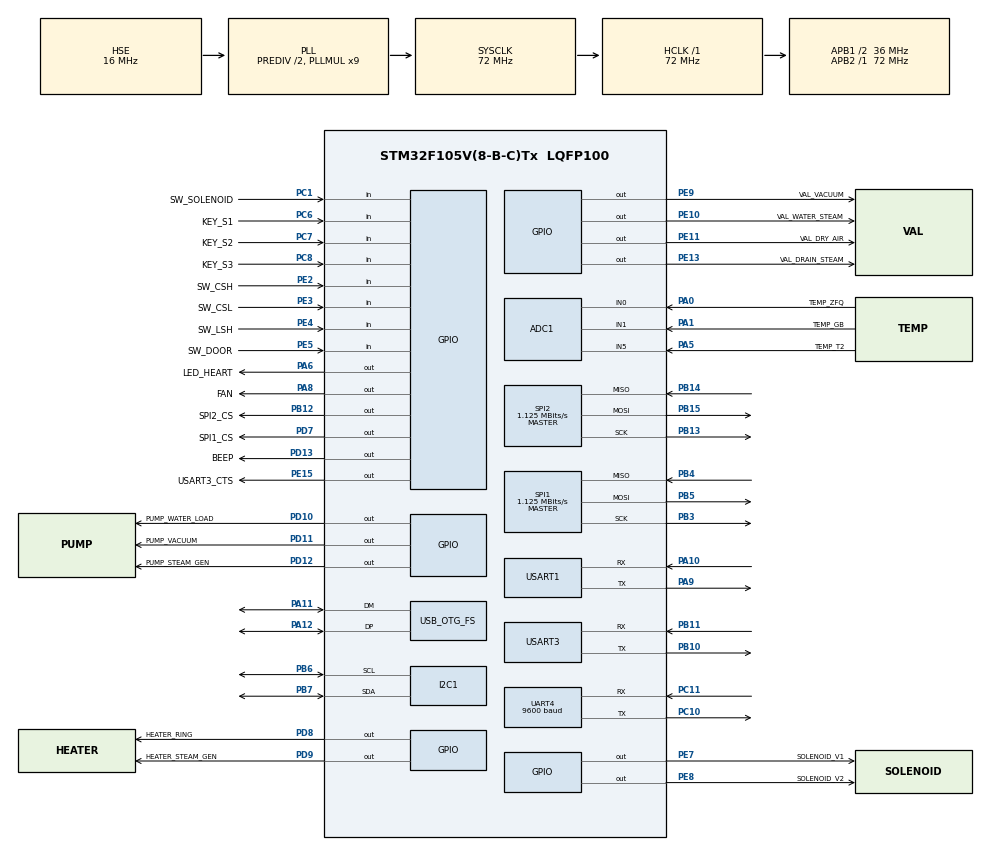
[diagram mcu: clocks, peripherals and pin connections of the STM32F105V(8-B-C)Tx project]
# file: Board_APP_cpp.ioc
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ADC1.Channel-0\#ChannelRegularConversion=ADC_CHANNEL_0
ADC1.ContinuousConvMode=DISABLE
ADC1.DiscontinuousConvMode=DISABLE
ADC1.NbrOfConversion=1
ADC1.NbrOfConversionFlag=1
ADC1.Rank-0\#ChannelRegularConversion=1
ADC1.SamplingTime-0\#ChannelRegularConversion=ADC_SAMPLETIME_28CYCLES_5
ADC1.master=1
Dma.I2C1_RX.1.Direction=DMA_PERIPH_TO_MEMORY
Dma.I2C1_RX.1.Instance=DMA1_Channel7
Dma.I2C1_RX.1.MemDataAlignment=DMA_MDATAALIGN_BYTE
Dma.I2C1_RX.1.MemInc=DMA_MINC_ENABLE
Dma.I2C1_RX.1.Mode=DMA_NORMAL
Dma.I2C1_RX.1.PeriphDataAlignment=DMA_PDATAALIGN_BYTE
Dma.I2C1_RX.1.PeriphInc=DMA_PINC_DISABLE
Dma.I2C1_RX.1.Priority=DMA_PRIORITY_LOW
Dma.I2C1_TX.2.Direction=DMA_MEMORY_TO_PERIPH
Dma.I2C1_TX.2.Instance=DMA1_Channel6
Dma.I2C1_TX.2.MemDataAlignment=DMA_MDATAALIGN_BYTE
Dma.I2C1_TX.2.MemInc=DMA_MINC_ENABLE
Dma.I2C1_TX.2.Mode=DMA_NORMAL
Dma.I2C1_TX.2.PeriphDataAlignment=DMA_PDATAALIGN_BYTE
Dma.I2C1_TX.2.PeriphInc=DMA_PINC_DISABLE
Dma.I2C1_TX.2.Priority=DMA_PRIORITY_LOW
Dma.Request0=USART3_RX
Dma.Request1=I2C1_RX
Dma.Request2=I2C1_TX
Dma.USART3_RX.0.Direction=DMA_PERIPH_TO_MEMORY
Dma.USART3_RX.0.Instance=DMA1_Channel3
Dma.USART3_RX.0.MemDataAlignment=DMA_MDATAALIGN_BYTE
Dma.USART3_RX.0.MemInc=DMA_MINC_ENABLE
Dma.USART3_RX.0.Mode=DMA_NORMAL
Dma.USART3_RX.0.PeriphDataAlignment=DMA_PDATAALIGN_BYTE
Dma.USART3_RX.0.PeriphInc=DMA_PINC_DISABLE
Dma.USART3_RX.0.Priority=DMA_PRIORITY_LOW
FREERTOS.Tasks01=taskAlive,-2,1024,StartTaskAlive,Default,NULL,Dynamic,NULL,NULL
FREERTOS.configTOTAL_HEAP_SIZE=8192
FREERTOS.configUSE_NEWLIB_REENTRANT=1
Mcu.Family=STM32F1
Mcu.Name=STM32F105V(8-B-C)Tx
Mcu.Package=LQFP100
NVIC.DMA1_Channel3_IRQn=true\:5\:0\:false\:false\:true\:true\:false\:true\:true
NVIC.DMA1_Channel6_IRQn=true\:5\:0\:false\:false\:true\:true\:false\:true\:true
NVIC.DMA1_Channel7_IRQn=true\:5\:0\:false\:false\:true\:true\:false\:true\:true
NVIC.PriorityGroup=NVIC_PRIORITYGROUP_4
NVIC.TIM6_IRQn=true\:0\:0\:true\:false\:true\:false\:false\:true\:true
NVIC.TimeBase=TIM6_IRQn
NVIC.TimeBaseIP=TIM6
NVIC.USART3_IRQn=true\:5\:0\:false\:false\:true\:true\:true\:true\:true
OSC_IN.Mode=HSE-External-Oscillator
OSC_IN.Signal=RCC_OSC_IN
OSC_OUT.Mode=HSE-External-Oscillator
OSC_OUT.Signal=RCC_OSC_OUT
PA0-WKUP.GPIO_Label=TEMP_ZFQ
PA0-WKUP.Signal=ADCx_IN0
PA1.GPIO_Label=TEMP_GB
PA1.Signal=ADCx_IN1
PA10.Mode=Asynchronous
PA10.Signal=USART1_RX
PA11.Mode=Host_Only
PA11.Signal=USB_OTG_FS_DM
PA12.Mode=Host_Only
PA12.Signal=USB_OTG_FS_DP
PA13.Mode=Serial_Wire
PA13.Signal=SYS_JTMS-SWDIO
PA14.Mode=Serial_Wire
PA14.Signal=SYS_JTCK-SWCLK
PA5.GPIO_Label=TEMP_T2
PA5.Signal=ADCx_IN5
PA6.GPIO_Label=LED_HEART
PA6.Signal=GPIO_Output
PA8.GPIO_Label=FAN
PA8.Signal=GPIO_Output
PA9.Mode=Asynchronous
PA9.Signal=USART1_TX
PB10.Mode=Asynchronous
PB10.Signal=USART3_TX
PB11.Mode=Asynchronous
PB11.Signal=USART3_RX
PB12.GPIO_Label=SPI2_CS
PB12.Signal=GPIO_Output
PB13.Mode=Full_Duplex_Master
PB13.Signal=SPI2_SCK
PB14.Mode=Full_Duplex_Master
PB14.Signal=SPI2_MISO
PB15.Mode=Full_Duplex_Master
PB15.Signal=SPI2_MOSI
PB3.Mode=Full_Duplex_Master
PB3.Signal=SPI1_SCK
PB4.Mode=Full_Duplex_Master
PB4.Signal=SPI1_MISO
PB5.Mode=Full_Duplex_Master
PB5.Signal=SPI1_MOSI
PB6.Mode=I2C
PB6.Signal=I2C1_SCL
PB7.Mode=I2C
PB7.Signal=I2C1_SDA
PC1.GPIO_Label=SW_SOLENOID
PC1.Signal=GPIO_Input
PC10.Mode=Asynchronous
PC10.Signal=UART4_TX
PC11.Mode=Asynchronous
PC11.Signal=UART4_RX
PC6.GPIO_Label=KEY_S1
PC6.Signal=GPIO_Input
PC7.GPIO_Label=KEY_S2
PC7.Signal=GPIO_Input
PC8.GPIO_Label=KEY_S3
PC8.Signal=GPIO_Input
PD10.GPIO_Label=PUMP_WATER_LOAD
PD10.Signal=GPIO_Output
PD11.GPIO_Label=PUMP_VACUUM
PD11.Signal=GPIO_Output
PD12.GPIO_Label=PUMP_STEAM_GEN
PD12.Signal=GPIO_Output
PD13.GPIO_Label=BEEP
PD13.Signal=GPIO_Output
PD7.GPIO_Label=SPI1_CS
PD7.Signal=GPIO_Output
PD8.GPIO_Label=HEATER_RING
PD8.Signal=GPIO_Output
PD9.GPIO_Label=HEATER_STEAM_GEN
PD9.Signal=GPIO_Output
PE10.GPIO_Label=VAL_WATER_STEAM
PE10.Signal=GPIO_Output
PE11.GPIO_Label=VAL_DRY_AIR
PE11.Signal=GPIO_Output
PE13.GPIO_Label=VAL_DRAIN_STEAM
PE13.Signal=GPIO_Output
PE15.GPIO_Label=USART3_CTS
PE15.Signal=GPIO_Output
PE2.GPIO_Label=SW_CSH
PE2.Signal=GPIO_Input
PE3.GPIO_Label=SW_CSL
PE3.Signal=GPIO_Input
PE4.GPIO_Label=SW_LSH
PE4.Signal=GPIO_Input
PE5.GPIO_Label=SW_DOOR
PE5.Signal=GPIO_Input
PE7.GPIO_Label=SOLENOID_V1
PE7.Signal=GPIO_Output
PE8.GPIO_Label=SOLENOID_V2
PE8.Signal=GPIO_Output
PE9.GPIO_Label=VAL_VACUUM
PE9.Signal=GPIO_Output
ProjectManager.HeapSize=0x200
ProjectManager.StackSize=0x400
ProjectManager.TargetToolchain=STM32CubeIDE
RCC.ADCPresc=RCC_ADCPCLK2_DIV6
RCC.AHBFreq_Value=72000000
RCC.APB1CLKDivider=RCC_HCLK_DIV2
RCC.APB1Freq_Value=36000000
RCC.APB1TimFreq_Value=72000000
RCC.APB2Freq_Value=72000000
RCC.APB2TimFreq_Value=72000000
RCC.HCLKFreq_Value=72000000
RCC.HSEDivPLL=RCC_HSE_PREDIV_DIV2
RCC.HSE_VALUE=16000000
RCC.PLLMUL=RCC_PLL_MUL9
RCC.PLLSourceVirtual=RCC_PLLSOURCE_HSE
RCC.SYSCLKFreq_VALUE=72000000
RCC.SYSCLKSource=RCC_SYSCLKSOURCE_PLLCLK
RCC.USBFreq_Value=48000000
SH.ADCx_IN0.0=ADC1_IN0,IN0
SH.ADCx_IN1.0=ADC1_IN1,IN1
SH.ADCx_IN5.0=ADC1_IN5,IN5
SPI1.BaudRatePrescaler=SPI_BAUDRATEPRESCALER_64
SPI1.CalculateBaudRate=1.125 MBits/s
SPI1.Direction=SPI_DIRECTION_2LINES
SPI1.Mode=SPI_MODE_MASTER
SPI1.VirtualType=VM_MASTER
SPI2.BaudRatePrescaler=SPI_BAUDRATEPRESCALER_32
SPI2.CalculateBaudRate=1.125 MBits/s
SPI2.Direction=SPI_DIRECTION_2LINES
SPI2.Mode=SPI_MODE_MASTER
SPI2.VirtualType=VM_MASTER
UART4.BaudRate=9600
UART4.VirtualMode=Asynchronous
USART1.VirtualMode=VM_ASYNC
USART3.VirtualMode=VM_ASYNC
USB_OTG_FS.VirtualMode=Host_Only
VP_FREERTOS_VS_CMSIS_V1.Mode=CMSIS_V1
VP_SYS_VS_tim6.Mode=TIM6
board=custom

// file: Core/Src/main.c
/* USER CODE BEGIN Header */
/**
  ******************************************************************************
  * @file           : main.c
  * @brief          : Main program body
  ******************************************************************************
  * @attention
  *
  * Copyright (c) 2023 STMicroelectronics.
  * All rights reserved.
  *
  * This software is licensed under terms that can be found in the LICENSE file
  * in the root directory of this software component.
  * If no LICENSE file comes with this software, it is provided AS-IS.
  *
  ******************************************************************************
  */
/* USER CODE END Header */
#include "main.h"
#include "cmsis_os.h"

ADC_HandleTypeDef hadc1;

I2C_HandleTypeDef hi2c1;
DMA_HandleTypeDef hdma_i2c1_rx;
DMA_HandleTypeDef hdma_i2c1_tx;

SPI_HandleTypeDef hspi1;
SPI_HandleTypeDef hspi2;

UART_HandleTypeDef huart4;
UART_HandleTypeDef huart1;
UART_HandleTypeDef huart3;
DMA_HandleTypeDef hdma_usart3_rx;

HCD_HandleTypeDef hhcd_USB_OTG_FS;

osThreadId taskAliveHandle;

void SystemClock_Config(void);
static void MX_GPIO_Init(void);
static void MX_DMA_Init(void);
static void MX_USART3_UART_Init(void);
static void MX_I2C1_Init(void);
static void MX_SPI2_Init(void);
static void MX_USB_OTG_FS_HCD_Init(void);
static void MX_USART1_UART_Init(void);
static void MX_UART4_Init(void);
static void MX_ADC1_Init(void);
static void MX_SPI1_Init(void);
void StartTaskAlive(void const * argument);

int main(void)
{

  /* MCU Configuration--------------------------------------------------------*/

  /* Reset of all peripherals, Initializes the Flash interface and the Systick. */
  HAL_Init();

  /* Configure the system clock */
  SystemClock_Config();

  /* Initialize all configured peripherals */
  MX_GPIO_Init();
  MX_DMA_Init();
  MX_USART3_UART_Init();
  MX_I2C1_Init();
  MX_SPI2_Init();
  MX_USB_OTG_FS_HCD_Init();
  MX_USART1_UART_Init();
  MX_UART4_Init();
  MX_ADC1_Init();
  MX_SPI1_Init();

  /* Create the thread(s) */
  /* definition and creation of taskAlive */
  osThreadDef(taskAlive, StartTaskAlive, osPriorityLow, 1, 1024);
  taskAliveHandle = osThreadCreate(osThread(taskAlive), NULL);

  /* Start scheduler */
  osKernelStart();

  /* We should never get here as control is now taken by the scheduler */
  /* Infinite loop */
  while (1)
  {

  }
}

void SystemClock_Config(void)
{
  RCC_OscInitTypeDef RCC_OscInitStruct = {0};
  RCC_ClkInitTypeDef RCC_ClkInitStruct = {0};
  RCC_PeriphCLKInitTypeDef PeriphClkInit = {0};

  /** Initializes the RCC Oscillators according to the specified parameters
  * in the RCC_OscInitTypeDef structure.
  */
  RCC_OscInitStruct.OscillatorType = RCC_OSCILLATORTYPE_HSE;
  RCC_OscInitStruct.HSEState = RCC_HSE_ON;
  RCC_OscInitStruct.HSEPredivValue = RCC_HSE_PREDIV_DIV2;
  RCC_OscInitStruct.HSIState = RCC_HSI_ON;
  RCC_OscInitStruct.Prediv1Source = RCC_PREDIV1_SOURCE_HSE;
  RCC_OscInitStruct.PLL.PLLState = RCC_PLL_ON;
  RCC_OscInitStruct.PLL.PLLSource = RCC_PLLSOURCE_HSE;
  RCC_OscInitStruct.PLL.PLLMUL = RCC_PLL_MUL9;
  RCC_OscInitStruct.PLL2.PLL2State = RCC_PLL_NONE;
  if (HAL_RCC_OscConfig(&RCC_OscInitStruct) != HAL_OK)
  {
    Error_Handler();
  }

  /** Initializes the CPU, AHB and APB buses clocks
  */
  RCC_ClkInitStruct.ClockType = RCC_CLOCKTYPE_HCLK|RCC_CLOCKTYPE_SYSCLK
                              |RCC_CLOCKTYPE_PCLK1|RCC_CLOCKTYPE_PCLK2;
  RCC_ClkInitStruct.SYSCLKSource = RCC_SYSCLKSOURCE_PLLCLK;
  RCC_ClkInitStruct.AHBCLKDivider = RCC_SYSCLK_DIV1;
  RCC_ClkInitStruct.APB1CLKDivider = RCC_HCLK_DIV2;
  RCC_ClkInitStruct.APB2CLKDivider = RCC_HCLK_DIV1;

  if (HAL_RCC_ClockConfig(&RCC_ClkInitStruct, FLASH_LATENCY_2) != HAL_OK)
  {
    Error_Handler();
  }
  PeriphClkInit.PeriphClockSelection = RCC_PERIPHCLK_ADC|RCC_PERIPHCLK_USB;
  PeriphClkInit.AdcClockSelection = RCC_ADCPCLK2_DIV6;
  PeriphClkInit.UsbClockSelection = RCC_USBCLKSOURCE_PLL_DIV3;
  if (HAL_RCCEx_PeriphCLKConfig(&PeriphClkInit) != HAL_OK)
  {
    Error_Handler();
  }

  /** Configure the Systick interrupt time
  */
  __HAL_RCC_PLLI2S_ENABLE();
}

static void MX_ADC1_Init(void)
{

  ADC_ChannelConfTypeDef sConfig = {0};

  /** Common config
  */
  hadc1.Instance = ADC1;
  hadc1.Init.ScanConvMode = ADC_SCAN_DISABLE;
  hadc1.Init.ContinuousConvMode = DISABLE;
  hadc1.Init.DiscontinuousConvMode = DISABLE;
  hadc1.Init.ExternalTrigConv = ADC_SOFTWARE_START;
  hadc1.Init.DataAlign = ADC_DATAALIGN_RIGHT;
  hadc1.Init.NbrOfConversion = 1;
  if (HAL_ADC_Init(&hadc1) != HAL_OK)
  {
    Error_Handler();
  }

  /** Configure Regular Channel
  */
  sConfig.Channel = ADC_CHANNEL_0;
  sConfig.Rank = ADC_REGULAR_RANK_1;
  sConfig.SamplingTime = ADC_SAMPLETIME_28CYCLES_5;
  if (HAL_ADC_ConfigChannel(&hadc1, &sConfig) != HAL_OK)
  {
    Error_Handler();
  }

}

static void MX_I2C1_Init(void)
{

  hi2c1.Instance = I2C1;
  hi2c1.Init.ClockSpeed = 100000;
  hi2c1.Init.DutyCycle = I2C_DUTYCYCLE_2;
  hi2c1.Init.OwnAddress1 = 0;
  hi2c1.Init.AddressingMode = I2C_ADDRESSINGMODE_7BIT;
  hi2c1.Init.DualAddressMode = I2C_DUALADDRESS_DISABLE;
  hi2c1.Init.OwnAddress2 = 0;
  hi2c1.Init.GeneralCallMode = I2C_GENERALCALL_DISABLE;
  hi2c1.Init.NoStretchMode = I2C_NOSTRETCH_DISABLE;
  if (HAL_I2C_Init(&hi2c1) != HAL_OK)
  {
    Error_Handler();
  }

}

static void MX_SPI1_Init(void)
{

  /* SPI1 parameter configuration*/
  hspi1.Instance = SPI1;
  hspi1.Init.Mode = SPI_MODE_MASTER;
  hspi1.Init.Direction = SPI_DIRECTION_2LINES;
  hspi1.Init.DataSize = SPI_DATASIZE_8BIT;
  hspi1.Init.CLKPolarity = SPI_POLARITY_LOW;
  hspi1.Init.CLKPhase = SPI_PHASE_1EDGE;
  hspi1.Init.NSS = SPI_NSS_SOFT;
  hspi1.Init.BaudRatePrescaler = SPI_BAUDRATEPRESCALER_64;
  hspi1.Init.FirstBit = SPI_FIRSTBIT_MSB;
  hspi1.Init.TIMode = SPI_TIMODE_DISABLE;
  hspi1.Init.CRCCalculation = SPI_CRCCALCULATION_DISABLE;
  hspi1.Init.CRCPolynomial = 10;
  if (HAL_SPI_Init(&hspi1) != HAL_OK)
  {
    Error_Handler();
  }

}

static void MX_SPI2_Init(void)
{

  /* SPI2 parameter configuration*/
  hspi2.Instance = SPI2;
  hspi2.Init.Mode = SPI_MODE_MASTER;
  hspi2.Init.Direction = SPI_DIRECTION_2LINES;
  hspi2.Init.DataSize = SPI_DATASIZE_8BIT;
  hspi2.Init.CLKPolarity = SPI_POLARITY_LOW;
  hspi2.Init.CLKPhase = SPI_PHASE_1EDGE;
  hspi2.Init.NSS = SPI_NSS_SOFT;
  hspi2.Init.BaudRatePrescaler = SPI_BAUDRATEPRESCALER_32;
  hspi2.Init.FirstBit = SPI_FIRSTBIT_MSB;
  hspi2.Init.TIMode = SPI_TIMODE_DISABLE;
  hspi2.Init.CRCCalculation = SPI_CRCCALCULATION_DISABLE;
  hspi2.Init.CRCPolynomial = 10;
  if (HAL_SPI_Init(&hspi2) != HAL_OK)
  {
    Error_Handler();
  }

}

static void MX_UART4_Init(void)
{

  huart4.Instance = UART4;
  huart4.Init.BaudRate = 9600;
  huart4.Init.WordLength = UART_WORDLENGTH_8B;
  huart4.Init.StopBits = UART_STOPBITS_1;
  huart4.Init.Parity = UART_PARITY_NONE;
  huart4.Init.Mode = UART_MODE_TX_RX;
  huart4.Init.HwFlowCtl = UART_HWCONTROL_NONE;
  huart4.Init.OverSampling = UART_OVERSAMPLING_16;
  if (HAL_UART_Init(&huart4) != HAL_OK)
  {
    Error_Handler();
  }

}

static void MX_USART1_UART_Init(void)
{

  huart1.Instance = USART1;
  huart1.Init.BaudRate = 115200;
  huart1.Init.WordLength = UART_WORDLENGTH_8B;
  huart1.Init.StopBits = UART_STOPBITS_1;
  huart1.Init.Parity = UART_PARITY_NONE;
  huart1.Init.Mode = UART_MODE_TX_RX;
  huart1.Init.HwFlowCtl = UART_HWCONTROL_NONE;
  huart1.Init.OverSampling = UART_OVERSAMPLING_16;
  if (HAL_UART_Init(&huart1) != HAL_OK)
  {
    Error_Handler();
  }

}

static void MX_USART3_UART_Init(void)
{

  huart3.Instance = USART3;
  huart3.Init.BaudRate = 115200;
  huart3.Init.WordLength = UART_WORDLENGTH_8B;
  huart3.Init.StopBits = UART_STOPBITS_1;
  huart3.Init.Parity = UART_PARITY_NONE;
  huart3.Init.Mode = UART_MODE_TX_RX;
  huart3.Init.HwFlowCtl = UART_HWCONTROL_NONE;
  huart3.Init.OverSampling = UART_OVERSAMPLING_16;
  if (HAL_UART_Init(&huart3) != HAL_OK)
  {
    Error_Handler();
  }

}

static void MX_USB_OTG_FS_HCD_Init(void)
{

  hhcd_USB_OTG_FS.Instance = USB_OTG_FS;
  hhcd_USB_OTG_FS.Init.Host_channels = 8;
  hhcd_USB_OTG_FS.Init.speed = HCD_SPEED_FULL;
  hhcd_USB_OTG_FS.Init.phy_itface = HCD_PHY_EMBEDDED;
  hhcd_USB_OTG_FS.Init.Sof_enable = DISABLE;
  if (HAL_HCD_Init(&hhcd_USB_OTG_FS) != HAL_OK)
  {
    Error_Handler();
  }

}

static void MX_DMA_Init(void)
{

  /* DMA controller clock enable */
  __HAL_RCC_DMA1_CLK_ENABLE();

  /* DMA interrupt init */
  /* DMA1_Channel3_IRQn interrupt configuration */
  HAL_NVIC_SetPriority(DMA1_Channel3_IRQn, 5, 0);
  HAL_NVIC_EnableIRQ(DMA1_Channel3_IRQn);
  /* DMA1_Channel6_IRQn interrupt configuration */
  HAL_NVIC_SetPriority(DMA1_Channel6_IRQn, 5, 0);
  HAL_NVIC_EnableIRQ(DMA1_Channel6_IRQn);
  /* DMA1_Channel7_IRQn interrupt configuration */
  HAL_NVIC_SetPriority(DMA1_Channel7_IRQn, 5, 0);
  HAL_NVIC_EnableIRQ(DMA1_Channel7_IRQn);

}

static void MX_GPIO_Init(void)
{
  GPIO_InitTypeDef GPIO_InitStruct = {0};

  /* GPIO Ports Clock Enable */
  __HAL_RCC_GPIOE_CLK_ENABLE();
  __HAL_RCC_GPIOC_CLK_ENABLE();
  __HAL_RCC_GPIOA_CLK_ENABLE();
  __HAL_RCC_GPIOB_CLK_ENABLE();
  __HAL_RCC_GPIOD_CLK_ENABLE();

  /*Configure GPIO pin Output Level */
  HAL_GPIO_WritePin(GPIOA, LED_HEART_Pin|FAN_Pin, GPIO_PIN_RESET);

  /*Configure GPIO pin Output Level */
  HAL_GPIO_WritePin(GPIOE, SOLENOID_V1_Pin|SOLENOID_V2_Pin|VAL_VACUUM_Pin|VAL_WATER_STEAM_Pin
                          |VAL_DRY_AIR_Pin|VAL_DRAIN_STEAM_Pin|USART3_CTS_Pin, GPIO_PIN_RESET);

  /*Configure GPIO pin Output Level */
  HAL_GPIO_WritePin(SPI2_CS_GPIO_Port, SPI2_CS_Pin, GPIO_PIN_RESET);

  /*Configure GPIO pin Output Level */
  HAL_GPIO_WritePin(GPIOD, HEATER_RING_Pin|HEATER_STEAM_GEN_Pin|PUMP_WATER_LOAD_Pin|PUMP_VACUUM_Pin
                          |PUMP_STEAM_GEN_Pin|BEEP_Pin|SPI1_CS_Pin, GPIO_PIN_RESET);

  /*Configure GPIO pins : SW_CSH_Pin SW_CSL_Pin SW_LSH_Pin SW_DOOR_Pin */
  GPIO_InitStruct.Pin = SW_CSH_Pin|SW_CSL_Pin|SW_LSH_Pin|SW_DOOR_Pin;
  GPIO_InitStruct.Mode = GPIO_MODE_INPUT;
  GPIO_InitStruct.Pull = GPIO_NOPULL;
  HAL_GPIO_Init(GPIOE, &GPIO_InitStruct);

  /*Configure GPIO pins : SW_SOLENOID_Pin KEY_S1_Pin KEY_S2_Pin KEY_S3_Pin */
  GPIO_InitStruct.Pin = SW_SOLENOID_Pin|KEY_S1_Pin|KEY_S2_Pin|KEY_S3_Pin;
  GPIO_InitStruct.Mode = GPIO_MODE_INPUT;
  GPIO_InitStruct.Pull = GPIO_NOPULL;
  HAL_GPIO_Init(GPIOC, &GPIO_InitStruct);

  /*Configure GPIO pins : LED_HEART_Pin FAN_Pin */
  GPIO_InitStruct.Pin = LED_HEART_Pin|FAN_Pin;
  GPIO_InitStruct.Mode = GPIO_MODE_OUTPUT_PP;
  GPIO_InitStruct.Pull = GPIO_NOPULL;
  GPIO_InitStruct.Speed = GPIO_SPEED_FREQ_LOW;
  HAL_GPIO_Init(GPIOA, &GPIO_InitStruct);

  /*Configure GPIO pins : SOLENOID_V1_Pin SOLENOID_V2_Pin VAL_VACUUM_Pin VAL_WATER_STEAM_Pin
                           VAL_DRY_AIR_Pin VAL_DRAIN_STEAM_Pin USART3_CTS_Pin */
  GPIO_InitStruct.Pin = SOLENOID_V1_Pin|SOLENOID_V2_Pin|VAL_VACUUM_Pin|VAL_WATER_STEAM_Pin
                          |VAL_DRY_AIR_Pin|VAL_DRAIN_STEAM_Pin|USART3_CTS_Pin;
  GPIO_InitStruct.Mode = GPIO_MODE_OUTPUT_PP;
  GPIO_InitStruct.Pull = GPIO_NOPULL;
  GPIO_InitStruct.Speed = GPIO_SPEED_FREQ_LOW;
  HAL_GPIO_Init(GPIOE, &GPIO_InitStruct);

  /*Configure GPIO pin : SPI2_CS_Pin */
  GPIO_InitStruct.Pin = SPI2_CS_Pin;
  GPIO_InitStruct.Mode = GPIO_MODE_OUTPUT_PP;
  GPIO_InitStruct.Pull = GPIO_NOPULL;
  GPIO_InitStruct.Speed = GPIO_SPEED_FREQ_LOW;
  HAL_GPIO_Init(SPI2_CS_GPIO_Port, &GPIO_InitStruct);

  /*Configure GPIO pins : HEATER_RING_Pin HEATER_STEAM_GEN_Pin PUMP_WATER_LOAD_Pin PUMP_VACUUM_Pin
                           PUMP_STEAM_GEN_Pin BEEP_Pin SPI1_CS_Pin */
  GPIO_InitStruct.Pin = HEATER_RING_Pin|HEATER_STEAM_GEN_Pin|PUMP_WATER_LOAD_Pin|PUMP_VACUUM_Pin
                          |PUMP_STEAM_GEN_Pin|BEEP_Pin|SPI1_CS_Pin;
  GPIO_InitStruct.Mode = GPIO_MODE_OUTPUT_PP;
  GPIO_InitStruct.Pull = GPIO_NOPULL;
  GPIO_InitStruct.Speed = GPIO_SPEED_FREQ_LOW;
  HAL_GPIO_Init(GPIOD, &GPIO_InitStruct);

}

void StartTaskAlive(void const * argument)
{
  /* USER CODE BEGIN 5 */
  /* Infinite loop */

	taskAliveC();

  /* USER CODE END 5 */
}

void HAL_TIM_PeriodElapsedCallback(TIM_HandleTypeDef *htim)
{
  if (htim->Instance == TIM6) {
    HAL_IncTick();
  }
}

void Error_Handler(void)
{
  __disable_irq();
  while (1)
  {
  }
}
